# Port_9_10_2 register map
Vendor: Texas Instruments
Peripheral module from a debugger description file (folder msp430).
Registers are 8-bit, read-write, reset 0x0 unless marked. A register's access mark holds for its fields unless they carry their own. Offsets are as the file gives them; lines under a group give offsets from that group; [hi:lo] are bit positions; {n}, {i} and the like mark numbered series; 'fields as' and 'values as' point back to an identical list; <NAME> marks a mode.

## Port_9/10
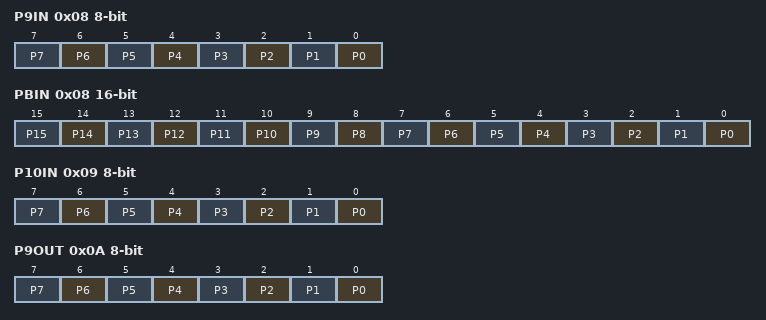
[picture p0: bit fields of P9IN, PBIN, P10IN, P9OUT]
0x08 P9IN — Port 9 Input
  [n] P{n} (n=0..7)
0x08 PBIN 16-bit — Port B Input
  [n] P{n} (n=0..15)
0x09 P10IN — Port 10 Input
  [n] P{n} (n=0..7)
0x0A P9OUT — Port 9 Output
  [n] P{n} (n=0..7)
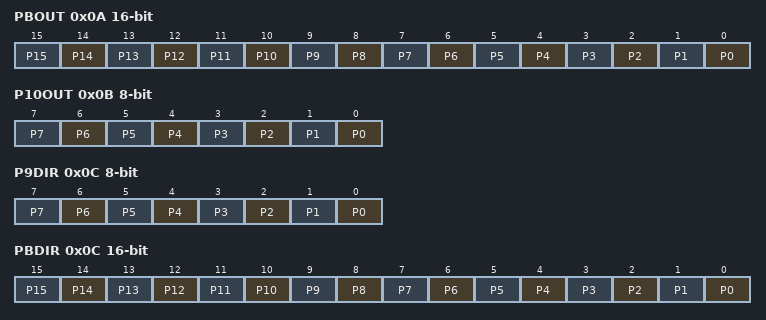
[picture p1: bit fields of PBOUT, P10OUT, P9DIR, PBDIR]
0x0A PBOUT 16-bit — Port B Output
  [n] P{n} (n=0..15)
0x0B P10OUT — Port 10 Output
  [n] P{n} (n=0..7)
0x0C P9DIR — Port 9 Direction
  [n] P{n} (n=0..7)
0x0C PBDIR 16-bit — Port B Direction
  [n] P{n} (n=0..15)
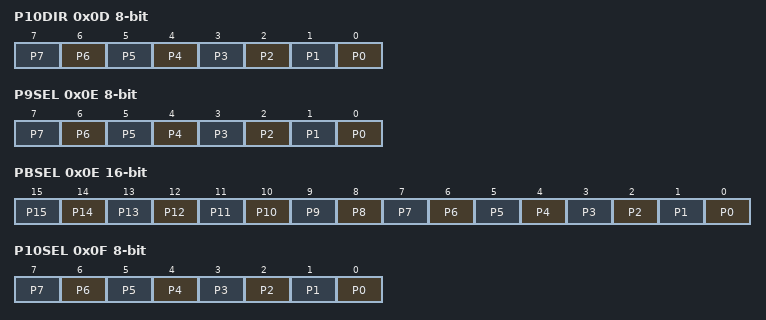
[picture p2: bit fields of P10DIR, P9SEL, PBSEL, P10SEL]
0x0D P10DIR — Port 10 Direction
  [n] P{n} (n=0..7)
0x0E P9SEL — Port 9 Selection
  [n] P{n} (n=0..7)
0x0E PBSEL 16-bit — Port B Selection
  [n] P{n} (n=0..15)
0x0F P10SEL — Port 10 Selection
  [n] P{n} (n=0..7)
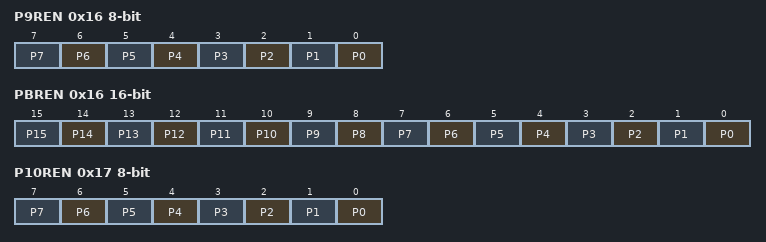
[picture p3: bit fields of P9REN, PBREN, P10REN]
0x16 P9REN — Port 9 Resistor Enable
  [n] P{n} (n=0..7)
0x16 PBREN 16-bit — Port B Resistor Enable
  [n] P{n} (n=0..15)
0x17 P10REN — Port 10 Resistor Enable
  [n] P{n} (n=0..7)
